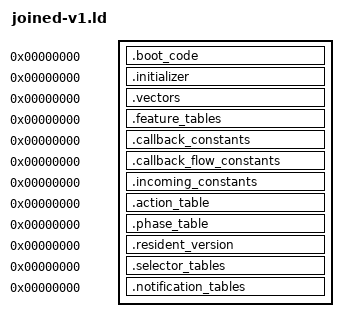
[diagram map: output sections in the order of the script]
OUTPUT_ARCH(riscv)
SECTIONS
{
 .boot_code 0 : SUBALIGN(2) { *(.boot_code)
  *(.text.tsl9_selector_notifications_provider_94ee)
  *(.text.tsl9_selector_notifications_provider_9ef0)
  *(.text.tsl9_state_request_records_block_9efa)
  *(.text.tsl9_state_request_records_block_9f06)
  *(.text.tsl9_state_request_records_block_9f0a)
  *(.text.tsl9_selector_notifications_provider_a9e8)
  *(.text.tsl9_state_request_records_block_aa00)
  *(.text.tsl9_state_request_records_block_aa04)
  *(.text.tsl9_state_request_records_block_aa0a)
  *(.text.tsl9_state_request_records_block_aa10)
  *(.text.tsl9_state_request_records_block_aa14)
  *(.text.tsl9_state_request_records_block_aa16)
  *(.text.tsl9_main_services_provider_aa18)
  *(.text.tsl9_selector_notifications_provider_abfc)
  *(.text.tsl9_selector_notifications_provider_da36)
  *(.text.tsl9_state_request_records_block_da4a)
  *(.text.tsl9_state_request_records_block_da4c)
  *(.text.tsl9_state_request_records_block_da4e)
  *(.text.tsl9_state_request_records_block_da52)
  *(.text.tsl9_state_request_records_block_da56)
  *(.text.tsl9_state_request_records_block_da5e)
  *(.text.tsl9_state_request_records_block_da60)
  *(.text.tsl9_state_request_records_block_da68)
  *(.text.tsl9_state_request_records_block_da6e)
  *(.text.tsl9_state_request_records_block_da72)
  *(.text.tsl9_feature_external_fba2)
  *(.text.tsl9_state_request_records_block_fbb6)
  *(.text.tsl9_state_request_records_block_fbbc)
  *(.text.tsl9_state_request_records_block_fbbe)
  *(.text.tsl9_state_request_records_block_fbd4)
  *(.text.tsl9_state_request_records_block_fbe4)
  *(.text.tsl9_state_request_records_block_fbf0)
  *(.text.tsl9_state_request_records_block_fbfe)
  *(.text.tsl9_state_request_records_block_fc0a)
  *(.text.tsl9_state_request_records_block_fc12)
  *(.text.tsl9_state_request_records_block_fc1e)
  *(.text.tsl9_state_request_records_block_fc28)
  *(.text.tsl9_state_request_records_block_fc2e)
  *(.text.tsl9_state_request_records_block_fc34)
  *(.text.tsl9_state_request_records_block_fc42)
  *(.text.tsl9_state_request_records_block_fc44)
  *(.text.tsl9_state_request_records_block_fc4e)
  *(.text.tsl9_state_request_records_block_fc54)
  *(.text.tsl9_state_request_records_block_fc56)
  *(.text.tsl9_state_request_records_block_fc60)
  *(.text.tsl9_state_request_records_block_fc6c)
  *(.text.tsl9_state_request_records_block_fc72)
  *(.text.tsl9_state_request_records_block_fc7a)
  *(.text.tsl9_state_request_records_block_fc82)
  *(.text.tsl9_state_request_records_block_fc86)
  *(.text.tsl9_state_request_records_block_fc88)
  *(.text.tsl9_state_request_records_block_fc90)
  *(.text.tsl9_state_request_records_block_fcb6)
  *(.text.tsl9_state_request_records_block_fcb8)
  *(.text.tsl9_state_request_records_block_fcda)
  *(.text.tsl9_state_request_records_block_fce6)
  *(.text.tsl9_state_request_records_block_fd06)
  *(.text.tsl9_state_request_records_block_fd1a)
  *(.text.tsl9_state_request_records_entry_fd3e)
  *(.text.tsl9_state_request_records_block_fd4c)
  *(.text.tsl9_state_request_records_block_fd52)
  *(.text.tsl9_state_request_records_block_fd58)
  *(.text.tsl9_state_request_records_entry_fd5e)
  *(.text.tsl9_state_request_records_entry_fd64)
  *(.text.tsl9_state_request_records_entry_fe1c)
  *(.text.tsl9_state_request_records_block_fe22)
  *(.text.tsl9_state_request_records_block_fe34)
  *(.text.tsl9_state_request_records_block_fe44)
  *(.text.tsl9_state_request_records_block_fe4c)
  *(.text.tsl9_state_request_records_block_fe58)
 }
 .initializer 0 : SUBALIGN(4) { *(.initializer) }
 .vectors 0 : SUBALIGN(4) { *(.vectors) }
 .feature_tables 0 : SUBALIGN(4) { *(.feature_tables) }
 .callback_constants 0 : SUBALIGN(4) { *(.callback_constants) }
 .callback_flow_constants 0 : SUBALIGN(4) { *(.callback_flow_constants) }
 .incoming_constants 0 : SUBALIGN(4) { *(.incoming_constants) }
 .action_table 0 : SUBALIGN(4) { *(.action_table) }
 .phase_table 0 : SUBALIGN(4) { *(.phase_table) }
 .resident_version 0 : SUBALIGN(4) { *(.resident_version) }
 .selector_tables 0 : SUBALIGN(1) {
  *(.rodata.tsl9_feature_state_records_static_data_1a4e4)
  *(.rodata.tsl9_feature_state_records_static_data_1a518)
  *(.rodata.tsl9_feature_state_records_static_data_1a528)
  *(.rodata.tsl9_feature_state_records_static_data_1a538)
 }
 .notification_tables 0 : SUBALIGN(4) {
  *(.rodata.tsl9_selector_notifications_table_1a13c)
  *(.rodata.tsl9_selector_notifications_table_1a150)
  *(.rodata.tsl9_selector_notifications_table_1a1c8)
  *(.rodata.tsl9_selector_notifications_table_1a314)
  *(.rodata.tsl9_selector_notifications_table_1a33c)
 }
 /DISCARD/ : { *(.comment) *(.riscv.attributes) *(.llvm_addrsig) }
}
